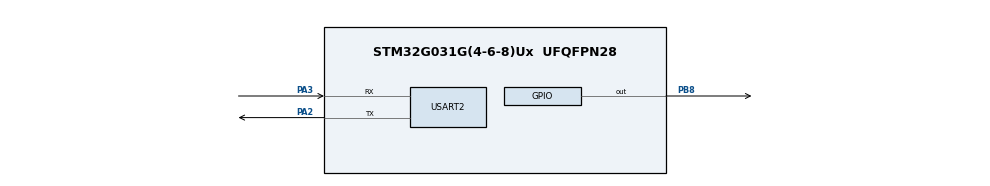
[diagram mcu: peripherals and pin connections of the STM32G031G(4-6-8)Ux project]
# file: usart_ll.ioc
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Mcu.Family=STM32G0
Mcu.Name=STM32G031G(4-6-8)Ux
Mcu.Package=UFQFPN28
PA2.Mode=Asynchronous
PA2.Signal=USART2_TX
PA3.Mode=Asynchronous
PA3.Signal=USART2_RX
PB8.Signal=GPIO_Output
ProjectManager.HeapSize=0x200
ProjectManager.StackSize=0x400
ProjectManager.TargetToolchain=STM32CubeIDE
RCC.AHBFreq_Value=16000000
RCC.CortexFreq_Value=16000000
RCC.EXTERNAL_CLOCK_VALUE=12288000
RCC.HCLKFreq_Value=16000000
RCC.HSE_VALUE=8000000
RCC.HSI_VALUE=16000000
RCC.LSE_VALUE=32768
RCC.SYSCLKFreq_VALUE=16000000
RCC.VCOOutputFreq_Value=128000000
USART2.VirtualMode-Asynchronous=VM_ASYNC
board=custom

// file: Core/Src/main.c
/* USER CODE BEGIN Header */
/**
  ******************************************************************************
  * @file           : main.c
  * @brief          : Main program body
  ******************************************************************************
  * @attention
  *
  * Copyright (c) 2023 STMicroelectronics.
  * All rights reserved.
  *
  * This software is licensed under terms that can be found in the LICENSE file
  * in the root directory of this software component.
  * If no LICENSE file comes with this software, it is provided AS-IS.
  *
  ******************************************************************************
  */
/* USER CODE END Header */
#include "main.h"
#include "usart.h"
#include "gpio.h"
#include "stdio.h"

void SystemClock_Config(void);

/* USER CODE BEGIN 0 */
#define PUTCHAR int __io_putchar(int ch)
PUTCHAR
{
//	HAL_UART_Transmit(&huart2, (uint8_t *) &ch, 1, HAL_MAX_DELAY);
	LL_USART_TransmitData8(USART2, (uint8_t) ch);
//	@brief  Check if the USART Transmit Data Register Empty or USART TX FIFO Not Full Flag is set or not
	while(!LL_USART_IsActiveFlag_TXE_TXFNF(USART2)){};
	return ch;
}

/* USER CODE END 0 */

int main(void)
{

  /* MCU Configuration--------------------------------------------------------*/

  /* Reset of all peripherals, Initializes the Flash interface and the Systick. */
  LL_APB2_GRP1_EnableClock(LL_APB2_GRP1_PERIPH_SYSCFG);
  LL_APB1_GRP1_EnableClock(LL_APB1_GRP1_PERIPH_PWR);

  /* SysTick_IRQn interrupt configuration */
  NVIC_SetPriority(SysTick_IRQn, 3);

  /* Configure the system clock */
  SystemClock_Config();

  /* Initialize all configured peripherals */
  MX_GPIO_Init();
  MX_USART2_UART_Init();

  /* Infinite loop */
  /* USER CODE BEGIN WHILE */
//  int n=0;
  while (1)
  {
    /* USER CODE END WHILE */
	  LL_GPIO_TogglePin(GPIOB, LL_GPIO_PIN_8);
//	  printf("%f\tHello world\r\n",(float)n);
	  printf("Hello world/r/n");
	  LL_mDelay(1000);
//	  n++;
  }
}

void SystemClock_Config(void)
{
  /* HSI configuration and activation */
  LL_RCC_HSI_Enable();
  while(LL_RCC_HSI_IsReady() != 1)
  {
  }

  /* Set AHB prescaler*/
  LL_RCC_SetAHBPrescaler(LL_RCC_SYSCLK_DIV_1);

  /* Sysclk activation on the HSI */
  LL_RCC_SetSysClkSource(LL_RCC_SYS_CLKSOURCE_HSI);
  while(LL_RCC_GetSysClkSource() != LL_RCC_SYS_CLKSOURCE_STATUS_HSI)
  {
  }

  /* Set APB1 prescaler*/
  LL_RCC_SetAPB1Prescaler(LL_RCC_APB1_DIV_1);

  LL_Init1msTick(16000000);

  /* Update CMSIS variable (which can be updated also through SystemCoreClockUpdate function) */
  LL_SetSystemCoreClock(16000000);
}

void Error_Handler(void)
{
  __disable_irq();
  while (1)
  {
  }
}
